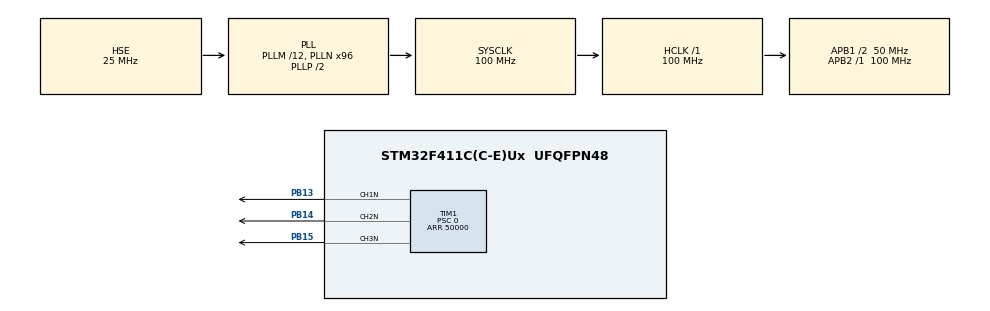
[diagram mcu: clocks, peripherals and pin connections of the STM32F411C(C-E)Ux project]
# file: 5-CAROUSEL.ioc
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Mcu.Family=STM32F4
Mcu.Name=STM32F411C(C-E)Ux
Mcu.Package=UFQFPN48
NVIC.PriorityGroup=NVIC_PRIORITYGROUP_4
PA13.Mode=Serial-Wire
PA13.Signal=SYS_JTMS-SWDIO
PA14.Mode=Serial-Wire
PA14.Signal=SYS_JTCK-SWCLK
PB13.Mode=PWM Generation1 CH1N
PB13.Signal=TIM1_CH1N
PB14.Mode=PWM Generation2 CH2N
PB14.Signal=TIM1_CH2N
PB15.Mode=PWM Generation3 CH3N
PB15.Signal=TIM1_CH3N
PC14-OSC32_IN.Mode=LSE-External-Oscillator
PC14-OSC32_IN.Signal=RCC_OSC32_IN
PC15-OSC32_OUT.Mode=LSE-External-Oscillator
PC15-OSC32_OUT.Signal=RCC_OSC32_OUT
PH0\ -\ OSC_IN.Mode=HSE-External-Oscillator
PH0\ -\ OSC_IN.Signal=RCC_OSC_IN
PH1\ -\ OSC_OUT.Mode=HSE-External-Oscillator
PH1\ -\ OSC_OUT.Signal=RCC_OSC_OUT
ProjectManager.HeapSize=0x400
ProjectManager.StackSize=0x200
ProjectManager.TargetToolchain=SW4STM32
RCC.48MHZClocksFreq_Value=50000000
RCC.AHBFreq_Value=100000000
RCC.APB1CLKDivider=RCC_HCLK_DIV2
RCC.APB1Freq_Value=50000000
RCC.APB1TimCLKDivider=1
RCC.APB1TimFreq_Value=50000000
RCC.APB2Freq_Value=100000000
RCC.APB2TimFreq_Value=100000000
RCC.CortexFreq_Value=100000000
RCC.HCLKFreq_Value=100000000
RCC.HSE_VALUE=25000000
RCC.HSI_VALUE=16000000
RCC.PLLM=12
RCC.PLLN=96
RCC.PLLSourceVirtual=RCC_PLLSOURCE_HSE
RCC.SYSCLKFreq_VALUE=100000000
RCC.SYSCLKSource=RCC_SYSCLKSOURCE_PLLCLK
RCC.VCOOutputFreq_Value=200000000
TIM1.Channel-PWM\ Generation2\ CH2N=TIM_CHANNEL_2
TIM1.Channel-PWM\ Generation3\ CH3N=TIM_CHANNEL_3
TIM1.OCNPolarity_1=TIM_OCNPOLARITY_LOW
TIM1.OCNPolarity_2=TIM_OCNPOLARITY_LOW
TIM1.OCNPolarity_3=TIM_OCNPOLARITY_LOW
TIM1.Period=50000
TIM1.Prescaler=0
board=5-CAROUSEL

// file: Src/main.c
/**
  ******************************************************************************
  * File Name          : main.c
  * Description        : Main program body
  ******************************************************************************
  *
  * COPYRIGHT(c) 2016 STMicroelectronics
  *
  * Redistribution and use in source and binary forms, with or without modification,
  * are permitted provided that the following conditions are met:
  *   1. Redistributions of source code must retain the above copyright notice,
  *      this list of conditions and the following disclaimer.
  *   2. Redistributions in binary form must reproduce the above copyright notice,
  *      this list of conditions and the following disclaimer in the documentation
  *      and/or other materials provided with the distribution.
  *   3. Neither the name of STMicroelectronics nor the names of its contributors
  *      may be used to endorse or promote products derived from this software
  *      without specific prior written permission.
  *
  * THIS SOFTWARE IS PROVIDED BY THE COPYRIGHT HOLDERS AND CONTRIBUTORS "AS IS"
  * AND ANY EXPRESS OR IMPLIED WARRANTIES, INCLUDING, BUT NOT LIMITED TO, THE
  * IMPLIED WARRANTIES OF MERCHANTABILITY AND FITNESS FOR A PARTICULAR PURPOSE ARE
  * DISCLAIMED. IN NO EVENT SHALL THE COPYRIGHT HOLDER OR CONTRIBUTORS BE LIABLE
  * FOR ANY DIRECT, INDIRECT, INCIDENTAL, SPECIAL, EXEMPLARY, OR CONSEQUENTIAL
  * DAMAGES (INCLUDING, BUT NOT LIMITED TO, PROCUREMENT OF SUBSTITUTE GOODS OR
  * SERVICES; LOSS OF USE, DATA, OR PROFITS; OR BUSINESS INTERRUPTION) HOWEVER
  * CAUSED AND ON ANY THEORY OF LIABILITY, WHETHER IN CONTRACT, STRICT LIABILITY,
  * OR TORT (INCLUDING NEGLIGENCE OR OTHERWISE) ARISING IN ANY WAY OUT OF THE USE
  * OF THIS SOFTWARE, EVEN IF ADVISED OF THE POSSIBILITY OF SUCH DAMAGE.
  *
  ******************************************************************************
  */
#include "stm32f4xx_hal.h"
#include "tim.h"
#include "gpio.h"

/* USER CODE BEGIN PV */
/* Private variables ---------------------------------------------------------*/

/* USER CODE END PV */

void SystemClock_Config(void);

/* USER CODE BEGIN PFP */
/* Private function prototypes -----------------------------------------------*/

/* USER CODE END PFP */

/* USER CODE BEGIN 0 */
typedef struct {
	double r;
	double g;
	double b;
} rgb;

typedef struct {
	double h;
	double s;
	double v;
} hsv;

rgb hsv2rgb(hsv in) {
	double hh, p, q, t, ff;
	long i;
	rgb out;

	if (in.s <= 0.0) {
		out.r = in.v;
		out.g = in.v;
		out.b = in.v;
		return out;
	}

	hh = in.h;
	if (hh >= 360.0)
		hh = 0.0;
	hh /= 60.0;

	i = (long) hh;
	ff = hh - i;

	p = in.v * (1.0 - in.s);
	q = in.v * (1.0 - (in.s * ff));
	t = in.v * (1.0 - (in.s * (1.0 - ff)));

	switch (i) {
	case 0:
		out.r = in.v;
		out.g = t;
		out.b = p;
		break;
	case 1:
		out.r = q;
		out.g = in.v;
		out.b = p;
		break;
	case 2:
		out.r = p;
		out.g = in.v;
		out.b = t;
		break;

	case 3:
		out.r = p;
		out.g = q;
		out.b = in.v;
		break;
	case 4:
		out.r = t;
		out.g = p;
		out.b = in.v;
		break;
	case 5:
	default:
		out.r = in.v;
		out.g = p;
		out.b = q;
		break;
	}
	return out;
}

void set_led_brightness(TIM_HandleTypeDef * timer, uint32_t channel,
		double brightness) {
	int32_t value = powf(brightness, 2.2) * 50000;
	__HAL_TIM_SET_COMPARE(timer, channel, value);
}

void set_color(hsv color_hsv) {
	rgb color_rgb = hsv2rgb(color_hsv);
	set_led_brightness(&htim1, TIM_CHANNEL_2, color_rgb.r);
	set_led_brightness(&htim1, TIM_CHANNEL_3, color_rgb.g);
	set_led_brightness(&htim1, TIM_CHANNEL_1, color_rgb.b);
}
/* USER CODE END 0 */

int main(void)
{

  /* MCU Configuration----------------------------------------------------------*/

  /* Reset of all peripherals, Initializes the Flash interface and the Systick. */
  HAL_Init();

  /* Configure the system clock */
  SystemClock_Config();

  /* Initialize all configured peripherals */
  MX_GPIO_Init();
  MX_TIM1_Init();

  /* USER CODE BEGIN 2 */
	HAL_TIMEx_PWMN_Start(&htim1, TIM_CHANNEL_1);
	HAL_TIMEx_PWMN_Start(&htim1, TIM_CHANNEL_2);
	HAL_TIMEx_PWMN_Start(&htim1, TIM_CHANNEL_3);
  /* USER CODE END 2 */

  /* Infinite loop */
	while (1) {

  /* USER CODE BEGIN 3 */
		hsv color;
		color.s = 1;

		for (color.h = 0; color.h < 360; color.h += 10) {
			for (color.v = 0; color.v < 1; color.v += 0.005) {
				set_color(color);
				HAL_Delay(1);
			}

			for (color.v = 1; color.v > 0; color.v -= 0.005) {
				set_color(color);
				HAL_Delay(1);
			}
		}
	}
  /* USER CODE END 3 */

}

/** System Clock Configuration
*/
void SystemClock_Config(void)
{

  RCC_OscInitTypeDef RCC_OscInitStruct;
  RCC_ClkInitTypeDef RCC_ClkInitStruct;

  __PWR_CLK_ENABLE();

  __HAL_PWR_VOLTAGESCALING_CONFIG(PWR_REGULATOR_VOLTAGE_SCALE1);

  RCC_OscInitStruct.OscillatorType = RCC_OSCILLATORTYPE_HSE;
  RCC_OscInitStruct.HSEState = RCC_HSE_ON;
  RCC_OscInitStruct.PLL.PLLState = RCC_PLL_ON;
  RCC_OscInitStruct.PLL.PLLSource = RCC_PLLSOURCE_HSE;
  RCC_OscInitStruct.PLL.PLLM = 12;
  RCC_OscInitStruct.PLL.PLLN = 96;
  RCC_OscInitStruct.PLL.PLLP = RCC_PLLP_DIV2;
  RCC_OscInitStruct.PLL.PLLQ = 4;
  HAL_RCC_OscConfig(&RCC_OscInitStruct);

  RCC_ClkInitStruct.ClockType = RCC_CLOCKTYPE_HCLK|RCC_CLOCKTYPE_SYSCLK
                              |RCC_CLOCKTYPE_PCLK1|RCC_CLOCKTYPE_PCLK2;
  RCC_ClkInitStruct.SYSCLKSource = RCC_SYSCLKSOURCE_PLLCLK;
  RCC_ClkInitStruct.AHBCLKDivider = RCC_SYSCLK_DIV1;
  RCC_ClkInitStruct.APB1CLKDivider = RCC_HCLK_DIV2;
  RCC_ClkInitStruct.APB2CLKDivider = RCC_HCLK_DIV1;
  HAL_RCC_ClockConfig(&RCC_ClkInitStruct, FLASH_LATENCY_3);

  HAL_SYSTICK_Config(HAL_RCC_GetHCLKFreq()/1000);

  HAL_SYSTICK_CLKSourceConfig(SYSTICK_CLKSOURCE_HCLK);

  /* SysTick_IRQn interrupt configuration */
  HAL_NVIC_SetPriority(SysTick_IRQn, 0, 0);
}

/************************ (C) COPYRIGHT STMicroelectronics *****END OF FILE****/
